# CC26x0 register map
File version: 2.3
CPU: CM3 r2p1, little endian, no MPU, no FPU, 3 interrupt priority bits
Registers are 32-bit, read-write, reset 0x0 unless marked. A register's access mark holds for its fields unless they carry their own. Offsets are from the block's base; [hi:lo] are bit positions; {n}, {i} and the like mark numbered series; 'fields as' and 'values as' point back to an identical list.

## CRYPTO — Crypto core with DMA capability and local key storage
Base 0x40024000
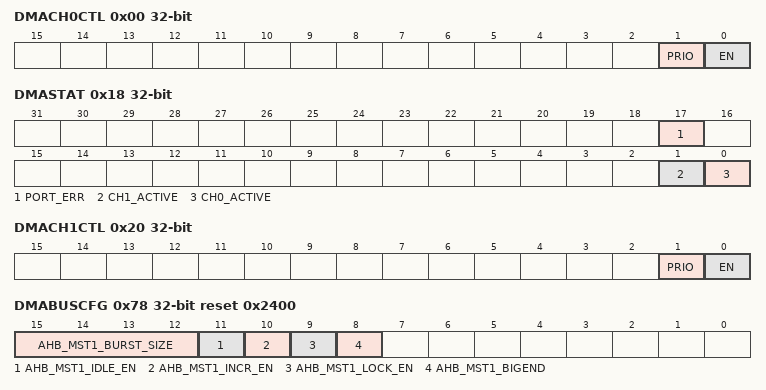
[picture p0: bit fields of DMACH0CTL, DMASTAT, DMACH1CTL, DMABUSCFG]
0x00 DMACH0CTL — DMA Channel 0 Control
  [1] PRIO, [0] EN
0x04 DMACH0EXTADDR — DMA Channel 0 External Address
  [31:0] ADDR
0x0C DMACH0LEN — DMA Channel 0 Length
  [15:0] LEN
0x18 DMASTAT ro — DMA Controller Status
  [17] PORT_ERR, [1] CH1_ACTIVE, [0] CH0_ACTIVE
0x1C DMASWRESET wo — DMA Controller Software Reset
  [0] RESET write-0-clears
0x20 DMACH1CTL — DMA Channel 1 Control
  [1] PRIO, [0] EN
0x24 DMACH1EXTADDR — DMA Channel 1 External Address
  [31:0] ADDR
0x2C DMACH1LEN — DMA Channel 1 Length
  [15:0] LEN
0x78 DMABUSCFG reset 0x2400 — DMA Controller Master Configuration
  [15:12] AHB_MST1_BURST_SIZE, [11] AHB_MST1_IDLE_EN, [10] AHB_MST1_INCR_EN, [9] AHB_MST1_LOCK_EN, [8] AHB_MST1_BIGEND
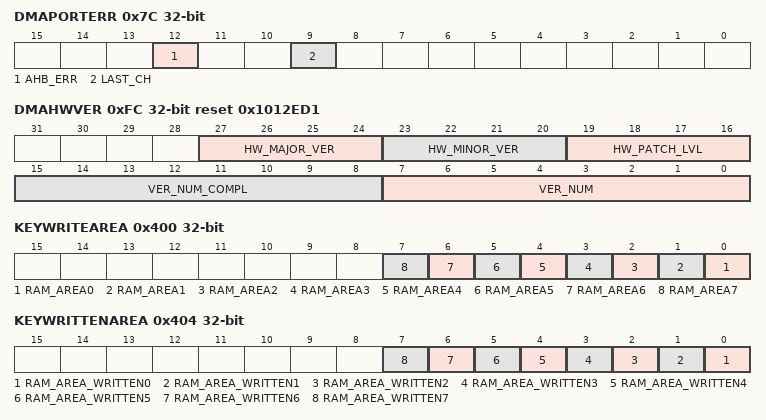
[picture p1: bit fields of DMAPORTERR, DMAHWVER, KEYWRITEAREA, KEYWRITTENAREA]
0x7C DMAPORTERR ro — DMA Controller Port Error
  [12] AHB_ERR, [9] LAST_CH
0xFC DMAHWVER ro reset 0x1012ED1 — DMA Controller Version
  [27:24] HW_MAJOR_VER, [23:20] HW_MINOR_VER, [19:16] HW_PATCH_LVL, [15:8] VER_NUM_COMPL, [7:0] VER_NUM
0x400 KEYWRITEAREA
  [n] RAM_AREA{n} (n=0..7)
0x404 KEYWRITTENAREA — Key Written Area Status This register shows which areas of the key store RAM contain valid written keys. When a new key needs to be written to the key store, on a location that is already occupied by a valid key, this key area must be cleared first. This can be done by writing this register before the new key is written to the key store memory. Attempting to write to a key area that already contains a valid key is not allowed and will result in an error.
  [n] RAM_AREA_WRITTEN{n} write-1-clears (n=0..7)
0x408 KEYSIZE reset 0x1 — Key Size This register defines the size of the keys that are written with DMA.
  [1:0] SIZE
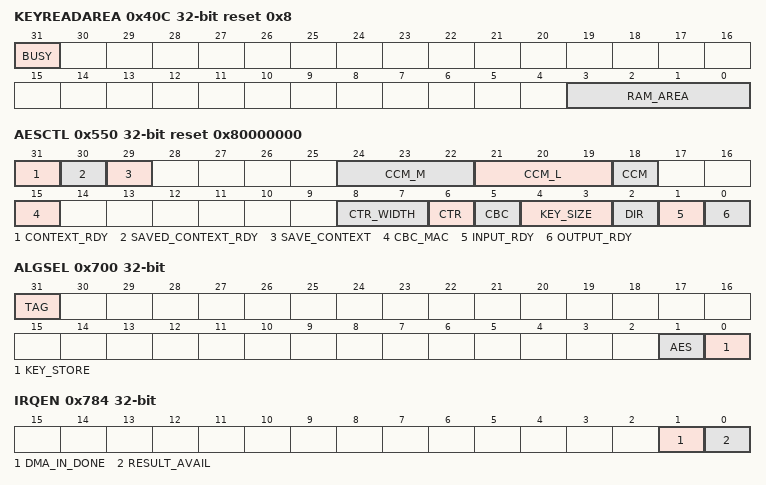
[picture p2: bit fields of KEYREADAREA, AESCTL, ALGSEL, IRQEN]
0x40C KEYREADAREA reset 0x8
  [31] BUSY, [3:0] RAM_AREA
{0x500+4i} AESKEY2{i} (i=0..3) wo — Clear AES_KEY2/GHASH Key
  [31:0] KEY2
{0x510+4i} AESKEY3{i} (i=0..3) wo — Clear AES_KEY3
  [31:0] KEY3
{0x540+4i} AESIV{i} (i=0..3) — AES Initialization Vector
  [31:0] IV
0x550 AESCTL reset 0x80000000 — AES Input/Output Buffer Control
  [31] CONTEXT_RDY, [30] SAVED_CONTEXT_RDY, [29] SAVE_CONTEXT, [24:22] CCM_M, [21:19] CCM_L, [18] CCM, [15] CBC_MAC, [8:7] CTR_WIDTH, [6] CTR, [5] CBC, [4:3] KEY_SIZE, [2] DIR, [1] INPUT_RDY, [0] OUTPUT_RDY
0x554 AESDATALEN0 wo — Crypto Data Length LSW
  [31:0] LEN_LSW
0x558 AESDATALEN1 wo — Crypto Data Length MSW
  [28:0] LEN_MSW
0x55C AESAUTHLEN wo — AES Authentication Length
  [31:0] LEN
0x560 AESDATAOUT0 ro (alternate view of AESDATAIN0) — Data Input/Output
  [31:0] DATA
{0x560+4i} AESDATAIN{i} wo (i=0..2) — AES Data Input/Output {i}
  [31:0] DATA
0x564 AESDATAOUT1 ro (alternate view of AESDATAIN1) — AES Data Input/Output 3
  [31:0] DATA
0x568 AESDATAOUT2 ro (alternate view of AESDATAIN2) — AES Data Input/Output 2
  [31:0] DATA
0x56C AESDATAOUT3 ro (alternate view of AESDATAIN3) — AES Data Input/Output 3
  [31:0] DATA
0x56C AESDATAIN3 wo — Data Input/Output
  [31:0] DATA
{0x570+4i} AESTAGOUT{i} (i=0..3) ro — AES Tag Output
  [31:0] TAG
0x700 ALGSEL — Master Algorithm Select This register configures the internal destination of the DMA controller.
  [31] TAG, [1] AES, [0] KEY_STORE
0x704 DMAPROTCTL — Master Protection Control
  [0] EN
0x740 SWRESET — Software Reset
  [0] RESET write-1-clears
0x780 IRQTYPE — Interrupt Configuration
  [0] IEN
0x784 IRQEN — Interrupt Enable
  [1] DMA_IN_DONE, [0] RESULT_AVAIL
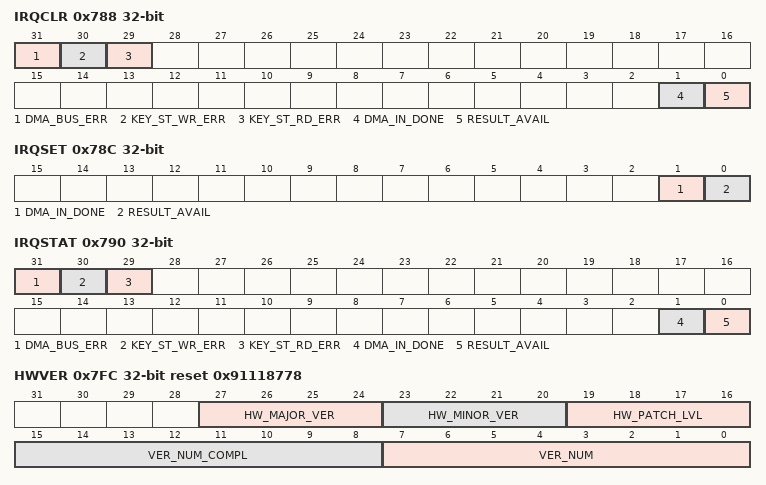
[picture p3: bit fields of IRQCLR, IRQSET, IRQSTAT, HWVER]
0x788 IRQCLR wo — Interrupt Clear
  [31] DMA_BUS_ERR, [30] KEY_ST_WR_ERR, [29] KEY_ST_RD_ERR, [1] DMA_IN_DONE, [0] RESULT_AVAIL
0x78C IRQSET wo — Interrupt Set
  [1] DMA_IN_DONE, [0] RESULT_AVAIL
0x790 IRQSTAT ro — Interrupt Status
  fields as IRQCLR
0x7FC HWVER ro reset 0x91118778 — CTRL Module Version
  fields as DMAHWVER
